# PIC32MK0512GPL064 register map
Vendor: Microchip
Registers are 32-bit, read-write, no defined reset value unless marked. A register's access mark holds for its fields unless they carry their own. Addresses are absolute, and some are shared; only a register's first bit layout is shown; [hi:lo] are bit positions; {n}, {i} and the like mark numbered series.

## EEPROM
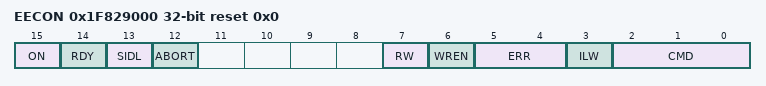
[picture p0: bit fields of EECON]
0x1F829000 EECON reset 0x0
  [15] ON, [14] RDY, [13] SIDL, [12] ABORT, [7] RW, [6] WREN, [5:4] ERR, [3] ILW, [2:0] CMD
0x1F829010 EEKEY wo reset 0x0
  [15:0] EEKEY
0x1F829020 EEADDR reset 0x0
  [13:0] EEADDR
0x1F829030 EEDATA reset 0x0

## cmp_control_upb
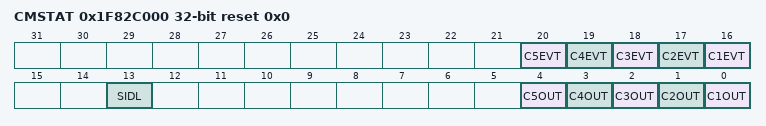
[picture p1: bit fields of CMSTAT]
0x1F82C000 CMSTAT reset 0x0
  [n+15] C{n}EVT ro (n=1..5), [13] SIDL, [n-1] C{n}OUT ro (n=1..5)

## CMP1
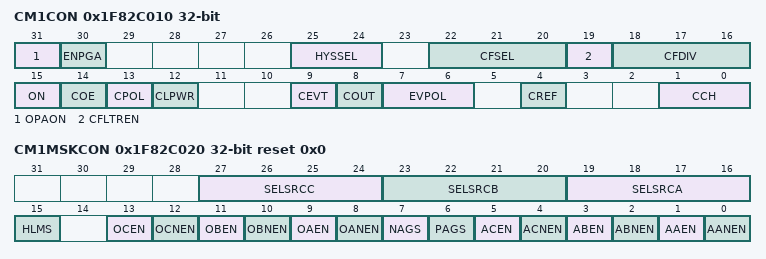
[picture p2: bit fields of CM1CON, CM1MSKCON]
0x1F82C010 CM1CON — (power-on value xx----00-00000000000--0000-0--00)
  [31] OPAON — Opamp Enable Bit
    1=Opamp Enabled and Connected to Pin; 0=Opamp is disabled and pin is released to other functions
  [30] ENPGA — Opamp Fixed Gain Enable bit
    1=Op amp is operating in Fixed Gain 1X mode; 0=Op amp is operating in Open Loop Mode
  [25:24] HYSSEL
  [22:20] CFSEL
  [19] CFLTREN
  [18:16] CFDIV
  [15] ON
  [14] COE
  [13] CPOL
  [12] CLPWR
  [9] CEVT
  [8] COUT ro
  [7:6] EVPOL
  [4] CREF
  [1:0] CCH
0x1F82C020 CM1MSKCON reset 0x0
  [27:24] SELSRCC, [23:20] SELSRCB, [19:16] SELSRCA, [15] HLMS, [13] OCEN, [12] OCNEN, [11] OBEN, [10] OBNEN, [9] OAEN, [8] OANEN, [7] NAGS, [6] PAGS, [5] ACEN, [4] ACNEN, [3] ABEN, [2] ABNEN, [1] AAEN, [0] AANEN

## CMP2
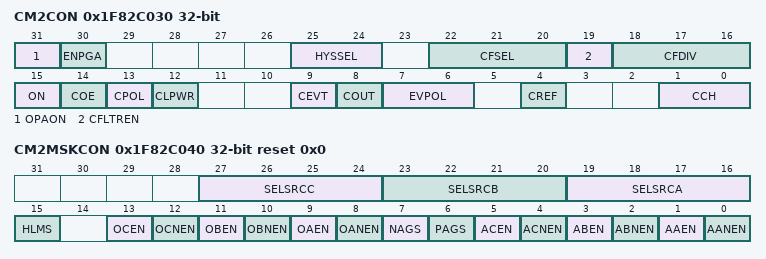
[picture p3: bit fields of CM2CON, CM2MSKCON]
0x1F82C030 CM2CON — (power-on value xx----00-00000000000--0000-0--00)
  [31] OPAON — Opamp Enable Bit
    1=Opamp Enabled and Connected to Pin; 0=Opamp is disabled and pin is released to other functions
  [30] ENPGA — Opamp Fixed Gain Enable bit
    1=Op amp is operating in Fixed Gain 1X mode; 0=Op amp is operating in Open Loop Mode
  [25:24] HYSSEL
  [22:20] CFSEL
  [19] CFLTREN
  [18:16] CFDIV
  [15] ON
  [14] COE
  [13] CPOL
  [12] CLPWR
  [9] CEVT
  [8] COUT ro
  [7:6] EVPOL
  [4] CREF
  [1:0] CCH
0x1F82C040 CM2MSKCON reset 0x0
  [27:24] SELSRCC, [23:20] SELSRCB, [19:16] SELSRCA, [15] HLMS, [13] OCEN, [12] OCNEN, [11] OBEN, [10] OBNEN, [9] OAEN, [8] OANEN, [7] NAGS, [6] PAGS, [5] ACEN, [4] ACNEN, [3] ABEN, [2] ABNEN, [1] AAEN, [0] AANEN

## CMP3
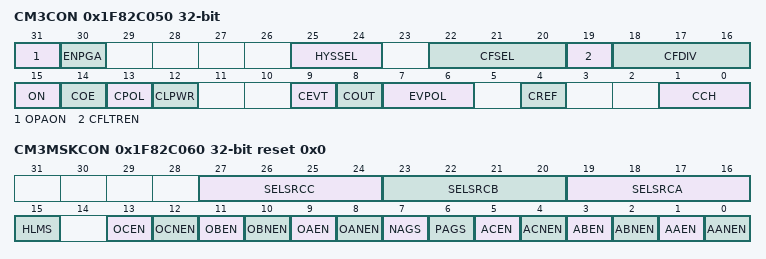
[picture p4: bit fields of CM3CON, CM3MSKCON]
0x1F82C050 CM3CON — (power-on value xx----00-00000000000--0000-0--00)
  [31] OPAON — Opamp Enable Bit
    1=Opamp Enabled and Connected to Pin; 0=Opamp is disabled and pin is released to other functions
  [30] ENPGA — Opamp Fixed Gain Enable bit
    1=Op amp is operating in Fixed Gain 1X mode; 0=Op amp is operating in Open Loop Mode
  [25:24] HYSSEL
  [22:20] CFSEL
  [19] CFLTREN
  [18:16] CFDIV
  [15] ON
  [14] COE
  [13] CPOL
  [12] CLPWR
  [9] CEVT
  [8] COUT ro
  [7:6] EVPOL
  [4] CREF
  [1:0] CCH
0x1F82C060 CM3MSKCON reset 0x0
  [27:24] SELSRCC, [23:20] SELSRCB, [19:16] SELSRCA, [15] HLMS, [13] OCEN, [12] OCNEN, [11] OBEN, [10] OBNEN, [9] OAEN, [8] OANEN, [7] NAGS, [6] PAGS, [5] ACEN, [4] ACNEN, [3] ABEN, [2] ABNEN, [1] AAEN, [0] AANEN

## CMP4
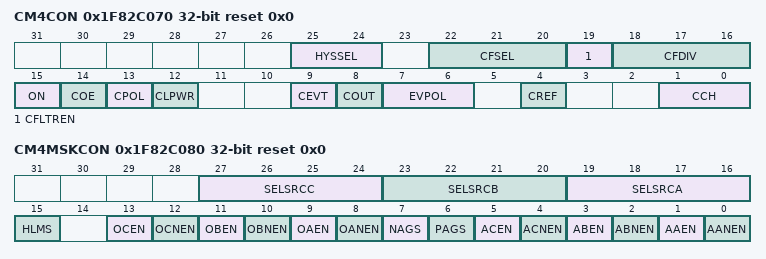
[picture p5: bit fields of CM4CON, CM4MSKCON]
0x1F82C070 CM4CON reset 0x0
  [25:24] HYSSEL, [22:20] CFSEL, [19] CFLTREN, [18:16] CFDIV, [15] ON, [14] COE, [13] CPOL, [12] CLPWR, [9] CEVT, [8] COUT ro, [7:6] EVPOL, [4] CREF, [1:0] CCH
0x1F82C080 CM4MSKCON reset 0x0
  [27:24] SELSRCC, [23:20] SELSRCB, [19:16] SELSRCA, [15] HLMS, [13] OCEN, [12] OCNEN, [11] OBEN, [10] OBNEN, [9] OAEN, [8] OANEN, [7] NAGS, [6] PAGS, [5] ACEN, [4] ACNEN, [3] ABEN, [2] ABNEN, [1] AAEN, [0] AANEN

## CMP5
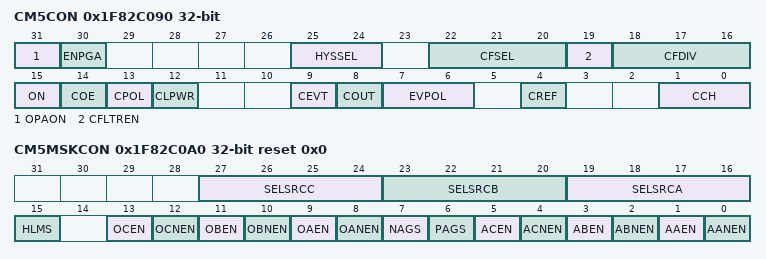
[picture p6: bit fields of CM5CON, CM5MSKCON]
0x1F82C090 CM5CON — (power-on value xx----00-00000000000--0000-0--00)
  [31] OPAON — Opamp Enable Bit
    1=Opamp Enabled and Connected to Pin; 0=Opamp is disabled and pin is released to other functions
  [30] ENPGA — Opamp Fixed Gain Enable bit
    1=Op amp is operating in Fixed Gain 1X mode; 0=Op amp is operating in Open Loop Mode
  [25:24] HYSSEL
  [22:20] CFSEL
  [19] CFLTREN
  [18:16] CFDIV
  [15] ON
  [14] COE
  [13] CPOL
  [12] CLPWR
  [9] CEVT
  [8] COUT ro
  [7:6] EVPOL
  [4] CREF
  [1:0] CCH
0x1F82C0A0 CM5MSKCON reset 0x0
  [27:24] SELSRCC, [23:20] SELSRCB, [19:16] SELSRCA, [15] HLMS, [13] OCEN, [12] OCNEN, [11] OBEN, [10] OBNEN, [9] OAEN, [8] OANEN, [7] NAGS, [6] PAGS, [5] ACEN, [4] ACNEN, [3] ABEN, [2] ABNEN, [1] AAEN, [0] AANEN
